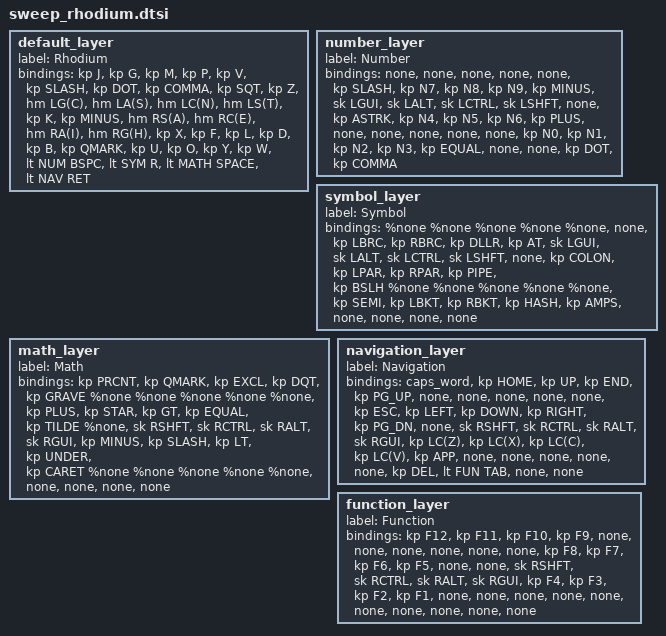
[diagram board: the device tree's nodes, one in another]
default_layer {
	label = "Rhodium";
	bindings = <
	// ----------+-----------+-----------+-----------+-----------||----------+-----------+-----------+-----------+-----------|
		&kp J		&kp G		&kp M		&kp P		&kp V		&kp SLASH	&kp DOT		&kp COMMA	&kp SQT		&kp Z 
	// ----------+-----------+-----------+-----------+-----------||----------+-----------+-----------+-----------+-----------|
		&hm LG(C)	&hm LA(S)	&hm LC(N)	&hm LS(T)	&kp K		&kp MINUS	&hm RS(A)	&hm RC(E) 	&hm RA(I)	&hm RG(H)
	// ----------+-----------+-----------+-----------+-----------||----------+-----------+-----------+-----------+-----------|
		&kp X		&kp F		&kp L		&kp D		&kp B		&kp QMARK   &kp U		&kp O		&kp Y		&kp W	
	// ----------+-----------+-----------+-----------+-----------||----------+-----------+-----------+-----------+-----------|
										&lt NUM BSPC	&lt SYM R	&lt MATH SPACE	&lt NAV RET
							        //---------------+-----------||--------------+--------------|
	>;
};

number_layer {
	label = "Number";
	bindings = <
	// ----------+-----------+-----------+-----------+-----------||----------+-----------+-----------+-----------+-----------|
		&none		&none		&none		&none		&none		&kp SLASH	&kp N7		&kp N8		&kp N9		&kp MINUS 
	// ----------+-----------+-----------+-----------+-----------||----------+-----------+-----------+-----------+-----------|
		&sk LGUI	&sk LALT	&sk LCTRL	&sk LSHFT	&none		&kp ASTRK	&kp N4		&kp N5 		&kp N6		&kp PLUS
	// ----------+-----------+-----------+-----------+-----------||----------+-----------+-----------+-----------+-----------|
		&none		&none		&none		&none		&none		&kp N0	    &kp N1		&kp N2		&kp N3		&kp EQUAL	
	// ----------+-----------+-----------+-----------+-----------||----------+-----------+-----------+-----------+-----------|
											&none		&none		&kp DOT		&kp COMMA
							            //-----------+-----------||----------+-----------|
	>;
};


symbol_layer {
	label = "Symbol";
	bindings = <
	// ----------+-----------+-----------+-----------+-----------||----------+-----------+-----------+-----------+-----------|
		%none		%none		%none		%none		%none		&none		&kp LBRC	&kp RBRC	&kp DLLR	&kp AT 
	// ----------+-----------+-----------+-----------+-----------||----------+-----------+-----------+-----------+-----------|
		&sk LGUI	&sk LALT	&sk LCTRL	&sk LSHFT	&none		&kp COLON	&kp LPAR	&kp RPAR 	&kp PIPE	&kp BSLH
	// ----------+-----------+-----------+-----------+-----------||----------+-----------+-----------+-----------+-----------|
		%none		%none		%none		%none		%none		&kp SEMI   	&kp LBKT	&kp RBKT 	&kp HASH	&kp AMPS	
	// ----------+-----------+-----------+-----------+-----------||----------+-----------+-----------+-----------+-----------|
											&none		&none 		&none 		&none
							        	//-----------+-----------||----------+-----------|
	>;
};

math_layer {
	label = "Math";
	bindings = <
	// ----------+-----------+-----------+-----------+-----------||----------+-----------+-----------+-----------+-----------|
		&kp PRCNT	&kp QMARK	&kp EXCL	&kp DQT		&kp GRAVE	%none		%none		%none		%none		%none 
	// ----------+-----------+-----------+-----------+-----------||----------+-----------+-----------+-----------+-----------|
		&kp PLUS	&kp STAR	&kp GT		&kp EQUAL	&kp TILDE	%none		&sk RSHFT	&sk RCTRL 	&sk RALT	&sk RGUI	
	// ----------+-----------+-----------+-----------+-----------||----------+-----------+-----------+-----------+-----------|
		&kp MINUS	&kp SLASH	&kp LT		&kp UNDER	&kp CARET	%none   	%none		%none 		%none		%none	
	// ----------+-----------+-----------+-----------+-----------||----------+-----------+-----------+-----------+-----------|
											&none		&none 		&none 		&none
							        	//-----------+-----------||----------+-----------|
	>;
};

navigation_layer {
	label = "Navigation";
	bindings = <
	// ----------+-----------+-----------+-----------+-----------||----------+-----------+-----------+-----------+-----------|
		&caps_word	&kp HOME	&kp UP		&kp END		&kp PG_UP	&none		&none		&none		&none		&none 
	// ----------+-----------+-----------+-----------+-----------||----------+-----------+-----------+-----------+-----------|
		&kp ESC 	&kp LEFT	&kp DOWN	&kp RIGHT	&kp PG_DN	&none		&sk RSHFT	&sk RCTRL 	&sk RALT	&sk RGUI
	// ----------+-----------+-----------+-----------+-----------||----------+-----------+-----------+-----------+-----------|
		&kp LC(Z)	&kp LC(X)	&kp LC(C)	&kp LC(V)	&kp APP		&none	    &none		&none		&none		&none	
	// ----------+-----------+-----------+-----------+-----------||----------+-----------+-----------+-----------+-----------|
											&kp DEL		&lt FUN TAB		&none		&none
							        //---------------+-----------||----------+-----------|
	>;
};

function_layer {
	label = "Function";
	bindings = <
	// ----------+-----------+-----------+-----------+-----------||---------+-----------+-----------+-----------+-----------|
		&kp F12		&kp F11		&kp F10		&kp F9	 	&none 		&none		&none		&none		&none		&none		
	// ----------+-----------+-----------+-----------+-----------||---------+-----------+-----------+-----------+-----------|
		&kp F8		&kp F7 		&kp F6		&kp F5		&none 		&none 		&sk RSHFT	&sk RCTRL	&sk RALT	&sk RGUI		
	// ----------+-----------+-----------+-----------+-----------||---------+-----------+-----------+-----------+-----------|
		&kp F4		&kp F3		&kp F2		&kp F1		&none 		&none		&none		&none		&none		&none		
	// ----------+-----------+-----------+-----------+-----------||---------+-----------+-----------+-----------+-----------|
											&none		&none		&none		&none
							            //-----------+-----------||----------+-----------|
	>;
};
